# STM32U083 register map
File version: 0.2
CPU: CM0+ r0p1, little endian, MPU, no FPU, 4 interrupt priority bits
Registers are 32-bit, read-write, reset 0x0 unless marked. A register's access mark holds for its fields unless they carry their own. Offsets are from the block's base; [hi:lo] are bit positions; <NAME> marks a mode.

## OPAMP — OPAMP address block description
Base 0x40007800
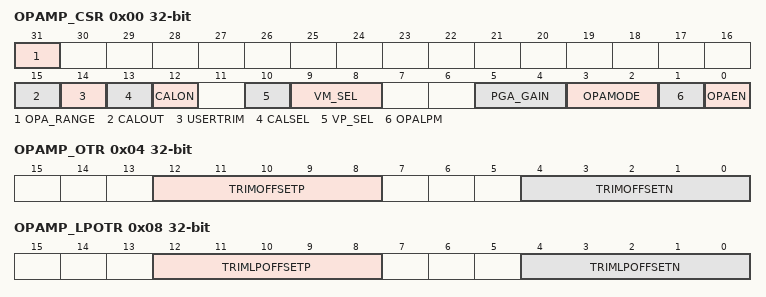
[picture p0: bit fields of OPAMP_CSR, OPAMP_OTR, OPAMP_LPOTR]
0x00 OPAMP_CSR access per field — OPAMP control/status register
  [31] OPA_RANGE rw — Operational amplifier power supply range for stability All AOP must be in power down to allow AOP-RANGE bit write. It applies to all AOP embedded in the product.
    0=Low range (VDDA < 2.4V); 1=High range (VDDA > 2.4V)
  [15] CALOUT ro — Operational amplifier calibration output During calibration mode offset is trimmed when this signal toggle.
  [14] USERTRIM rw — allows to switch from factory AOP offset trimmed values to AOP offset user trimmed values This bit is active for both mode normal and low-power.
    0=factory trim code used; 1=user trim code used
  [13] CALSEL rw — Calibration selection
    0=NMOS calibration (200mV applied on OPAMP inputs); 1=PMOS calibration (VDDA-200mV applied on OPAMP inputs)
  [12] CALON rw — Calibration mode enabled
    0=Normal mode; 1=Calibration mode (all switches opened by HW)
  [10] VP_SEL rw — Non inverted input selection
    0=GPIO connected to VINP; 1=DAC connected to VINP
  [9:8] VM_SEL rw — Inverting input selection These bits are used only when OPAMODE = 00, 01 or 10. 1x: Inverting input not externally connected. These configurations are valid only when OPAMODE = 10 (PGA mode)
    0=GPIO connected to VINM (valid also in PGA mode for filtering)
  [5:4] PGA_GAIN rw — Operational amplifier Programmable amplifier gain value
    0=internal PGA Gain 2; 1=internal PGA Gain 4; 2=internal PGA Gain 8; 3=internal PGA Gain 16
  [3:2] OPAMODE rw — Operational amplifier PGA mode
    0=internal PGA disable; 1=internal PGA disable; 2=internal PGA enable, gain programmed in PGA_GAIN; 3=internal follower
  [1] OPALPM rw — Operational amplifier Low Power Mode The operational amplifier must be disable to change this configuration.
    0=operational amplifier in normal mode; 1=operational amplifier in low-power mode
  [0] OPAEN rw — Operational amplifier Enable
    0=operational amplifier disabled; 1=operational amplifier enabled
0x04 OPAMP_OTR (reset mask 0xFFFF0000) — OPAMP offset trimming register in normal mode
  [12:8] TRIMOFFSETP — Trim for PMOS differential pairs
  [4:0] TRIMOFFSETN — Trim for NMOS differential pairs
0x08 OPAMP_LPOTR (reset mask 0xFFFF0000) — OPAMP offset trimming register in low-power mode
  [12:8] TRIMLPOFFSETP — Low-power mode trim for PMOS differential pairs
  [4:0] TRIMLPOFFSETN — Low-power mode trim for NMOS differential pairs

## VREFBUF — VREFBUF address block description
Base 0x40010030
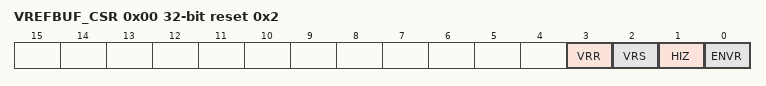
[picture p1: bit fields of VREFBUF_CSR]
0x00 VREFBUF_CSR access per field reset 0x2 — VREFBUF control and status register
  [3] VRR ro — Voltage reference buffer ready
    0=the voltage reference buffer output is not ready; 1=the voltage reference buffer output reached the requested level
  [2] VRS rw — Voltage reference scale This bit selects the value generated by the voltage reference buffer.
    0=Voltage reference set to V<sub>REF_OUT1</sub> (around 2.0481V); 1=Voltage reference set to V<sub>REF_OUT2</sub> (around 2.51V)
  [1] HIZ rw — High impedance mode This bit controls the analog switch to connect or not the V<sub>REF+</sub> pin. Refer to Table172: VREF buffer modes for the mode descriptions depending on ENVR bit configuration.
    0=V<sub>REF+</sub> pin is internally connected to the voltage reference buffer output; 1=V<sub>REF+</sub> pin is high impedance
  [0] ENVR rw — Voltage reference buffer mode enable This bit is used to enable the voltage reference buffer mode.
    0=Internal voltage reference mode disable (external voltage reference mode); 1=Internal voltage reference mode (reference buffer enable or hold mode) enable
0x04 VREFBUF_CCR (reset mask 0xFFFFFF00) — VREFBUF calibration control register
  [5:0] TRIM

## WWDG — WWDG address block description
Base 0x40002C00
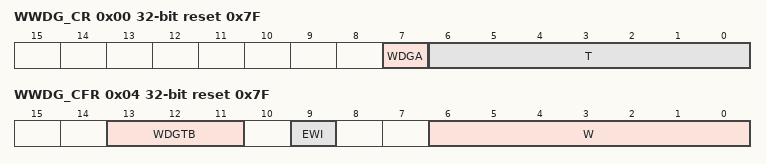
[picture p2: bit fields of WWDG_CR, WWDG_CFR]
0x00 WWDG_CR reset 0x7F — WWDG control register
  [7] WDGA — Activation bit This bit is set by software and only cleared by hardware after a reset. When WDGA=1, the watchdog can generate a reset.
    0=Watchdog disabled; 1=Watchdog enabled
  [6:0] T — 7-bit counter (MSB to LSB) These bits contain the value of the watchdog counter, decremented every (4096 x 2<sup>WDGTB[2:0]</sup>) PCLK cycles. A reset is produced when it is decremented from 0x40 to 0x3F (T6 becomes cleared).
0x04 WWDG_CFR reset 0x7F — WWDG configuration register
  [13:11] WDGTB — Timer base The timebase of the prescaler can be modified as follows:
    0=CK counter clock (PCLK div 4096) div 1; 1=CK counter clock (PCLK div 4096) div 2; 2=CK counter clock (PCLK div 4096) div 4; 3=CK counter clock (PCLK div 4096) div 8; 4=CK counter clock (PCLK div 4096) div 16; 5=CK counter clock (PCLK div 4096) div 32; 6=CK counter clock (PCLK div 4096) div 64; 7=CK counter clock (PCLK div 4096) div 128
  [9] EWI — Early wake-up interrupt enable Set by software and cleared by hardware after a reset. When set, an interrupt occurs whenever the counter reaches the value 0x40.
  [6:0] W — 7-bit window value These bits contain the window value to be compared with the down-counter.
0x08 WWDG_SR — WWDG status register
  [0] EWIF — Early wake-up interrupt flag This bit is set by hardware when the counter has reached the value 0x40. It must be cleared by software by writing 0. Writing 1 has no effect. This bit is also set if the interrupt is not enabled.
